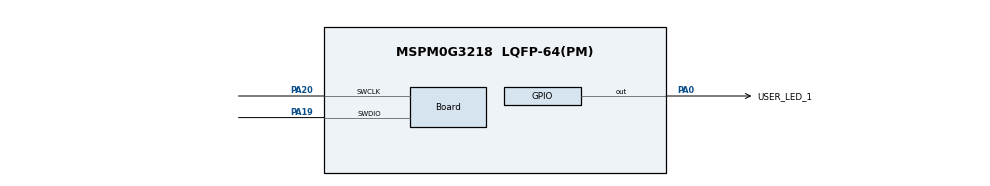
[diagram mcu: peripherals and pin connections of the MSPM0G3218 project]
//@cliArgs --device "MSPM0G321X" --package "LQFP-64(PM)" --part "Default"
//@v2CliArgs --device "MSPM0G3218" --package "LQFP-64(PM)"
// @cliArgs --board /ti/boards/LP_MSPM0G3218 --rtos nortos

/**
 * Import the modules used in this configuration.
 */
const ADC12  = scripting.addModule("/ti/driverlib/ADC12", {}, false);
const ADC121 = ADC12.addInstance();
const Board  = scripting.addModule("/ti/driverlib/Board");
const GPIO   = scripting.addModule("/ti/driverlib/GPIO", {}, false);
const GPIO1  = GPIO.addInstance();
const SYSCTL = scripting.addModule("/ti/driverlib/SYSCTL");

/**
 * Write custom configuration values to the imported modules.
 */
ADC121.$name                       = "ADC12_0";
ADC121.sampClkSrc                  = "DL_ADC12_CLOCK_ULPCLK";
ADC121.sampClkDiv                  = "DL_ADC12_CLOCK_DIVIDE_8";
ADC121.sampleTime0                 = "125 us";
ADC121.enabledInterrupts           = ["DL_ADC12_INTERRUPT_MEM0_RESULT_LOADED"];
ADC121.powerDownMode               = "DL_ADC12_POWER_DOWN_MODE_MANUAL";
ADC121.adcMem0chansel              = "DL_ADC12_INPUT_CHAN_14";
ADC121.peripheral.$assign          = "ADC1";
ADC121.peripheral.adcPin14.$assign = "PB27";


Board.peripheral.$assign          = "DEBUGSS";
Board.peripheral.swclkPin.$assign = "PA20";
Board.peripheral.swdioPin.$assign = "PA19";

GPIO1.$name                          = "GPIO_LEDS";
GPIO1.port                           = "PORTA";
GPIO1.portSegment                    = "Lower";
GPIO1.associatedPins[0].$name        = "USER_LED_1";
GPIO1.associatedPins[0].assignedPin  = "0";
GPIO1.associatedPins[0].initialValue = "SET";
GPIO1.associatedPins[0].pin.$assign  = "PA0";

SYSCTL.forceDefaultClkConfig = true;
SYSCTL.clockTreeEn           = true;

const ProjectConfig              = scripting.addModule("/ti/project_config/ProjectConfig", {}, false);
ProjectConfig.migrationCondition = true;
